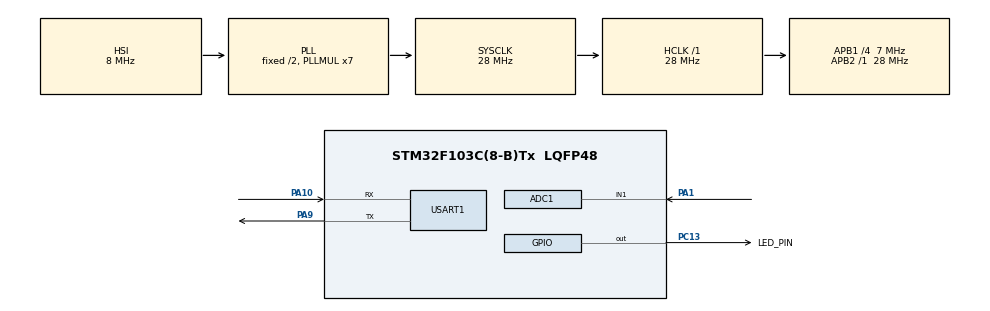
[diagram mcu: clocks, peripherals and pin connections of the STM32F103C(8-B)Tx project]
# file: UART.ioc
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ADC1.Channel-0\#ChannelRegularConversion=ADC_CHANNEL_1
ADC1.ContinuousConvMode=ENABLE
ADC1.NbrOfConversion=1
ADC1.NbrOfConversionFlag=1
ADC1.Rank-0\#ChannelRegularConversion=1
ADC1.SamplingTime-0\#ChannelRegularConversion=ADC_SAMPLETIME_239CYCLES_5
ADC1.master=1
Dma.ADC1.0.Direction=DMA_PERIPH_TO_MEMORY
Dma.ADC1.0.Instance=DMA1_Channel1
Dma.ADC1.0.MemDataAlignment=DMA_MDATAALIGN_HALFWORD
Dma.ADC1.0.MemInc=DMA_MINC_ENABLE
Dma.ADC1.0.Mode=DMA_CIRCULAR
Dma.ADC1.0.PeriphDataAlignment=DMA_PDATAALIGN_HALFWORD
Dma.ADC1.0.PeriphInc=DMA_PINC_DISABLE
Dma.ADC1.0.Priority=DMA_PRIORITY_HIGH
Dma.Request0=ADC1
FREERTOS.BinarySemaphores01=myBinarySem01,Static,myBinarySem01ControlBlock
FREERTOS.Tasks01=defaultTask,0,128,StartDefaultTask,Default,NULL,Dynamic,NULL,NULL
FREERTOS.configUSE_NEWLIB_REENTRANT=1
Mcu.Family=STM32F1
Mcu.Name=STM32F103C(8-B)Tx
Mcu.Package=LQFP48
NVIC.DMA1_Channel1_IRQn=true\:5\:0\:false\:false\:true\:true\:false\:true\:true
NVIC.PriorityGroup=NVIC_PRIORITYGROUP_4
NVIC.TIM1_UP_IRQn=true\:15\:0\:false\:false\:true\:false\:false\:true\:true
NVIC.TimeBase=TIM1_UP_IRQn
NVIC.TimeBaseIP=TIM1
PA1.Signal=ADCx_IN1
PA10.Mode=Asynchronous
PA10.Signal=USART1_RX
PA13.Mode=Serial_Wire
PA13.Signal=SYS_JTMS-SWDIO
PA14.Mode=Serial_Wire
PA14.Signal=SYS_JTCK-SWCLK
PA9.Mode=Asynchronous
PA9.Signal=USART1_TX
PC13-TAMPER-RTC.GPIO_Label=LED_PIN
PC13-TAMPER-RTC.Signal=GPIO_Output
ProjectManager.HeapSize=0x200
ProjectManager.StackSize=0x400
ProjectManager.TargetToolchain=STM32CubeIDE
RCC.AHBFreq_Value=28000000
RCC.APB1CLKDivider=RCC_HCLK_DIV4
RCC.APB1Freq_Value=7000000
RCC.APB1TimFreq_Value=14000000
RCC.APB2Freq_Value=28000000
RCC.APB2TimFreq_Value=28000000
RCC.HCLKFreq_Value=28000000
RCC.PLLMUL=RCC_PLL_MUL7
RCC.SYSCLKFreq_VALUE=28000000
RCC.SYSCLKSource=RCC_SYSCLKSOURCE_PLLCLK
RCC.USBFreq_Value=28000000
SH.ADCx_IN1.0=ADC1_IN1,IN1
USART1.VirtualMode=VM_ASYNC
VP_FREERTOS_VS_CMSIS_V1.Mode=CMSIS_V1
VP_SYS_VS_tim1.Mode=TIM1
board=custom

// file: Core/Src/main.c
/* USER CODE BEGIN Header */
/**
  ******************************************************************************
  * @file           : main.c
  * @brief          : Main program body
  ******************************************************************************
  * @attention
  *
  * Copyright (c) 2024 STMicroelectronics.
  * All rights reserved.
  *
  * This software is licensed under terms that can be found in the LICENSE file
  * in the root directory of this software component.
  * If no LICENSE file comes with this software, it is provided AS-IS.
  *
  ******************************************************************************
  */
/* USER CODE END Header */
#include "main.h"
#include "cmsis_os.h"

/* USER CODE BEGIN Includes */
#include <string.h>
/* USER CODE END Includes */

/* USER CODE BEGIN PD */
#define LEN_BUFFER 4096
#define LEN_DATA_UART 512
/* USER CODE END PD */

ADC_HandleTypeDef hadc1;
DMA_HandleTypeDef hdma_adc1;

UART_HandleTypeDef huart1;

osThreadId defaultTaskHandle;
osSemaphoreId myBinarySem01Handle;
osStaticSemaphoreDef_t myBinarySem01ControlBlock;
/* USER CODE BEGIN PV */
uint8_t cant_conversiones_adc = 0;
/* USER CODE END PV */

void SystemClock_Config(void);
static void MX_GPIO_Init(void);
static void MX_DMA_Init(void);
static void MX_USART1_UART_Init(void);
static void MX_ADC1_Init(void);
void StartDefaultTask(void const * argument);

/* USER CODE BEGIN 0 */
uint16_t rawValues[LEN_BUFFER];
/* USER CODE END 0 */

int main(void)
{

  /* MCU Configuration--------------------------------------------------------*/

  /* Reset of all peripherals, Initializes the Flash interface and the Systick. */
  HAL_Init();

  /* Configure the system clock */
  SystemClock_Config();

  /* Initialize all configured peripherals */
  MX_GPIO_Init();
  MX_DMA_Init();
  MX_USART1_UART_Init();
  MX_ADC1_Init();

  /* Create the semaphores(s) */
  /* definition and creation of myBinarySem01 */
  osSemaphoreStaticDef(myBinarySem01, &myBinarySem01ControlBlock);
  myBinarySem01Handle = osSemaphoreCreate(osSemaphore(myBinarySem01), 0);

  /* Create the thread(s) */
  /* definition and creation of defaultTask */
  osThreadDef(defaultTask, StartDefaultTask, osPriorityNormal, 0, 128);
  defaultTaskHandle = osThreadCreate(osThread(defaultTask), NULL);

  /* Start scheduler */
  osKernelStart();

  /* We should never get here as control is now taken by the scheduler */
  /* Infinite loop */
  /* USER CODE BEGIN WHILE */

  /* Starts the ADC in DMA mode*/

//  uint16_t temp;

  while (1)
  {
//	HAL_GPIO_TogglePin(LED_PIN_GPIO_Port, LED_PIN_Pin);
//	for (int i = 0; i < 4098; i++) {
//		temp = rawValues[0] * 3300 / 4095;
//		HAL_UART_Transmit(&huart1, temp, 2, HAL_MAX_DELAY);
//	}
//	HAL_Delay(1000);
    /* USER CODE END WHILE */

  }
}

void SystemClock_Config(void)
{
  RCC_OscInitTypeDef RCC_OscInitStruct = {0};
  RCC_ClkInitTypeDef RCC_ClkInitStruct = {0};
  RCC_PeriphCLKInitTypeDef PeriphClkInit = {0};

  /** Initializes the RCC Oscillators according to the specified parameters
  * in the RCC_OscInitTypeDef structure.
  */
  RCC_OscInitStruct.OscillatorType = RCC_OSCILLATORTYPE_HSI;
  RCC_OscInitStruct.HSIState = RCC_HSI_ON;
  RCC_OscInitStruct.HSICalibrationValue = RCC_HSICALIBRATION_DEFAULT;
  RCC_OscInitStruct.PLL.PLLState = RCC_PLL_ON;
  RCC_OscInitStruct.PLL.PLLSource = RCC_PLLSOURCE_HSI_DIV2;
  RCC_OscInitStruct.PLL.PLLMUL = RCC_PLL_MUL7;
  if (HAL_RCC_OscConfig(&RCC_OscInitStruct) != HAL_OK)
  {
    Error_Handler();
  }

  /** Initializes the CPU, AHB and APB buses clocks
  */
  RCC_ClkInitStruct.ClockType = RCC_CLOCKTYPE_HCLK|RCC_CLOCKTYPE_SYSCLK
                              |RCC_CLOCKTYPE_PCLK1|RCC_CLOCKTYPE_PCLK2;
  RCC_ClkInitStruct.SYSCLKSource = RCC_SYSCLKSOURCE_PLLCLK;
  RCC_ClkInitStruct.AHBCLKDivider = RCC_SYSCLK_DIV1;
  RCC_ClkInitStruct.APB1CLKDivider = RCC_HCLK_DIV4;
  RCC_ClkInitStruct.APB2CLKDivider = RCC_HCLK_DIV1;

  if (HAL_RCC_ClockConfig(&RCC_ClkInitStruct, FLASH_LATENCY_1) != HAL_OK)
  {
    Error_Handler();
  }
  PeriphClkInit.PeriphClockSelection = RCC_PERIPHCLK_ADC;
  PeriphClkInit.AdcClockSelection = RCC_ADCPCLK2_DIV2;
  if (HAL_RCCEx_PeriphCLKConfig(&PeriphClkInit) != HAL_OK)
  {
    Error_Handler();
  }
}

static void MX_ADC1_Init(void)
{

  ADC_ChannelConfTypeDef sConfig = {0};

  /** Common config
  */
  hadc1.Instance = ADC1;
  hadc1.Init.ScanConvMode = ADC_SCAN_DISABLE;
  hadc1.Init.ContinuousConvMode = ENABLE;
  hadc1.Init.DiscontinuousConvMode = DISABLE;
  hadc1.Init.ExternalTrigConv = ADC_SOFTWARE_START;
  hadc1.Init.DataAlign = ADC_DATAALIGN_RIGHT;
  hadc1.Init.NbrOfConversion = 1;
  if (HAL_ADC_Init(&hadc1) != HAL_OK)
  {
    Error_Handler();
  }

  /** Configure Regular Channel
  */
  sConfig.Channel = ADC_CHANNEL_1;
  sConfig.Rank = ADC_REGULAR_RANK_1;
  sConfig.SamplingTime = ADC_SAMPLETIME_239CYCLES_5;
  if (HAL_ADC_ConfigChannel(&hadc1, &sConfig) != HAL_OK)
  {
    Error_Handler();
  }

}

static void MX_USART1_UART_Init(void)
{

  huart1.Instance = USART1;
  huart1.Init.BaudRate = 115200;
  huart1.Init.WordLength = UART_WORDLENGTH_8B;
  huart1.Init.StopBits = UART_STOPBITS_1;
  huart1.Init.Parity = UART_PARITY_NONE;
  huart1.Init.Mode = UART_MODE_TX_RX;
  huart1.Init.HwFlowCtl = UART_HWCONTROL_NONE;
  huart1.Init.OverSampling = UART_OVERSAMPLING_16;
  if (HAL_UART_Init(&huart1) != HAL_OK)
  {
    Error_Handler();
  }

}

static void MX_DMA_Init(void)
{

  /* DMA controller clock enable */
  __HAL_RCC_DMA1_CLK_ENABLE();

  /* DMA interrupt init */
  /* DMA1_Channel1_IRQn interrupt configuration */
  HAL_NVIC_SetPriority(DMA1_Channel1_IRQn, 5, 0);
  HAL_NVIC_EnableIRQ(DMA1_Channel1_IRQn);

}

static void MX_GPIO_Init(void)
{
  GPIO_InitTypeDef GPIO_InitStruct = {0};

  /* GPIO Ports Clock Enable */
  __HAL_RCC_GPIOC_CLK_ENABLE();
  __HAL_RCC_GPIOA_CLK_ENABLE();

  /*Configure GPIO pin Output Level */
  HAL_GPIO_WritePin(LED_PIN_GPIO_Port, LED_PIN_Pin, GPIO_PIN_RESET);

  /*Configure GPIO pin : LED_PIN_Pin */
  GPIO_InitStruct.Pin = LED_PIN_Pin;
  GPIO_InitStruct.Mode = GPIO_MODE_OUTPUT_PP;
  GPIO_InitStruct.Pull = GPIO_NOPULL;
  GPIO_InitStruct.Speed = GPIO_SPEED_FREQ_LOW;
  HAL_GPIO_Init(LED_PIN_GPIO_Port, &GPIO_InitStruct);

}

/* USER CODE BEGIN 4 */

//void HAL_ADC_ConvCpltCallback(ADC_HandleTypeDef* hadc) {
//	cant_conversiones_adc++;
//	if (cant_conversiones_adc >= LEN_DATA_UART) {
//		osSemaphoreRelease(myBinarySem01Handle);
//		cant_conversiones_adc %= LEN_DATA_UART;
//	}
//}
/* USER CODE END 4 */

void StartDefaultTask(void const * argument)
{
  /* USER CODE BEGIN 5 */
  uint8_t position = 0;
  const uint8_t value_reset = LEN_BUFFER / LEN_DATA_UART;
  HAL_ADC_Start_DMA(&hadc1, (uint32_t*)rawValues, LEN_BUFFER);
  /* Infinite loop */
  for(;;)
  {
//	  osSemaphoreWait(myBinarySem01Handle, 0);
	  HAL_UART_Transmit(&huart1, (uint8_t *)rawValues + position * LEN_DATA_UART, LEN_DATA_UART, HAL_MAX_DELAY);
	  position++;
	  position %= value_reset;
	  vTaskDelay(pdMS_TO_TICKS(.5));
  }
  /* USER CODE END 5 */
}

void HAL_TIM_PeriodElapsedCallback(TIM_HandleTypeDef *htim)
{
  if (htim->Instance == TIM1) {
    HAL_IncTick();
  }
}

void Error_Handler(void)
{
  __disable_irq();
  while (1)
  {
  }
}
